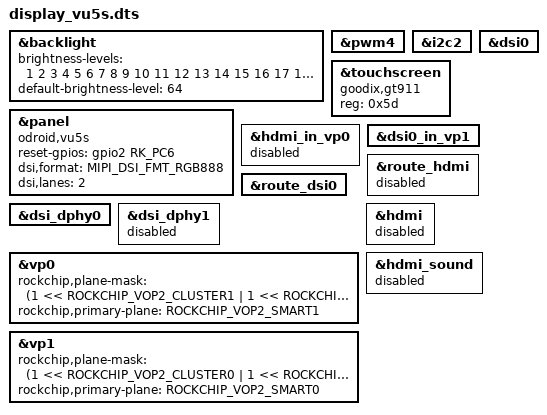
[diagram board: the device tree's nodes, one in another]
/dts-v1/;
/plugin/;

#include <dt-bindings/gpio/gpio.h>
#include <dt-bindings/pinctrl/rockchip.h>
#include <dt-bindings/interrupt-controller/irq.h>
#include <dt-bindings/interrupt-controller/arm-gic.h>
#include <dt-bindings/display/rockchip_vop.h>
#include <dt-bindings/display/drm_mipi_dsi.h>

/{
	fragment@0 {
		target = <&backlight>;

		__overlay__ {
			status = "okay";
			brightness-levels = <
				1   2   3   4   5   6   7   8
				9   10  11  12  13  14  15  16
				17  18  19  20  21  22  23  24
				25  26  27  28  29  30  31  32
				33  34  35  36  37  38  39  40
				41  42  43  44  45  46  47  48
				49  50  51  52  53  54  55  56
				57  58  59  60  61  62  63  64
				65  66  67  68  69  70  71  72
				73  74  75  76  77  78  79  80
				81  82  83  84  85  86  87  88
				89  90  91  92  93  94  95  96
				97  98  99  100 101 102 103 104
				105 106 107 108 109 110 111 112
				113 114 115 116 117 118 119 120
				121 122 123 124 125 126 127 128
				>;
			default-brightness-level = <64>;
		};
	};

	fragment@1 {
		target = <&pwm4>;

		__overlay__ {
			status = "okay";
		};
	};

	fragment@2 {
		target = <&i2c2>;

		__overlay__ {
			status = "okay";
		};
	};

	fragment@3 {
		target = <&touchscreen>;

		#address-cells = <1>;
		#size-cells = <0>;

		__overlay__ {
			status = "okay";

			compatible = "goodix,gt911";
			reg = <0x5d>;
		};
	};

	fragment@4 {
		target = <&dsi0>;

		__overlay__ {
			status = "okay";
		};
	};

	fragment@5 {
		target = <&panel>;

		__overlay__ {
			status = "okay";
			compatible = "odroid,vu5s";

			reset-gpios = <&gpio2 RK_PC6 GPIO_ACTIVE_HIGH>;

			dsi,format = <MIPI_DSI_FMT_RGB888>;
			dsi,lanes = <2>;
		};
	};

	fragment@6 {
		target = <&hdmi_in_vp0>;

		__overlay__ {
			status = "disabled";
		};
	};

	fragment@7 {
		target = <&dsi0_in_vp1>;

		__overlay__ {
			status = "okay";
		};
	};

	fragment@8 {
		target = <&route_hdmi>;

		__overlay__ {
			status = "disabled";
		};
	};

	fragment@9 {
		target = <&route_dsi0>;

		__overlay__ {
			status = "okay";
		};
	};

	fragment@10 {
		target = <&dsi_dphy0>;

		__overlay__ {
			status = "okay";
		};
	};

	fragment@11 {
		target = <&dsi_dphy1>;

		__overlay__ {
			status = "disabled";
		};
	};

	fragment@12 {
		target = <&vp0>;

		__overlay__ {
			rockchip,plane-mask = <(1 << ROCKCHIP_VOP2_CLUSTER1
					| 1 << ROCKCHIP_VOP2_ESMART1
					| 1 << ROCKCHIP_VOP2_SMART1)>;
			rockchip,primary-plane = <ROCKCHIP_VOP2_SMART1>;
		};
	};

	fragment@13 {
		target = <&vp1>;

		__overlay__ {
			rockchip,plane-mask = <(1 << ROCKCHIP_VOP2_CLUSTER0
					| 1 << ROCKCHIP_VOP2_ESMART0
					| 1 << ROCKCHIP_VOP2_SMART0)>;
			rockchip,primary-plane = <ROCKCHIP_VOP2_SMART0>;
		};
	};

	fragment@14 {
		target = <&hdmi>;

		__overlay__ {
			status = "disabled";
		};
	};

	fragment@15 {
		target = <&hdmi_in_vp0>;

		__overlay__ {
			status = "disabled";
		};
	};

	fragment@16 {
		target = <&hdmi_sound>;

		__overlay__ {
			status = "disabled";
		};
	};
};
